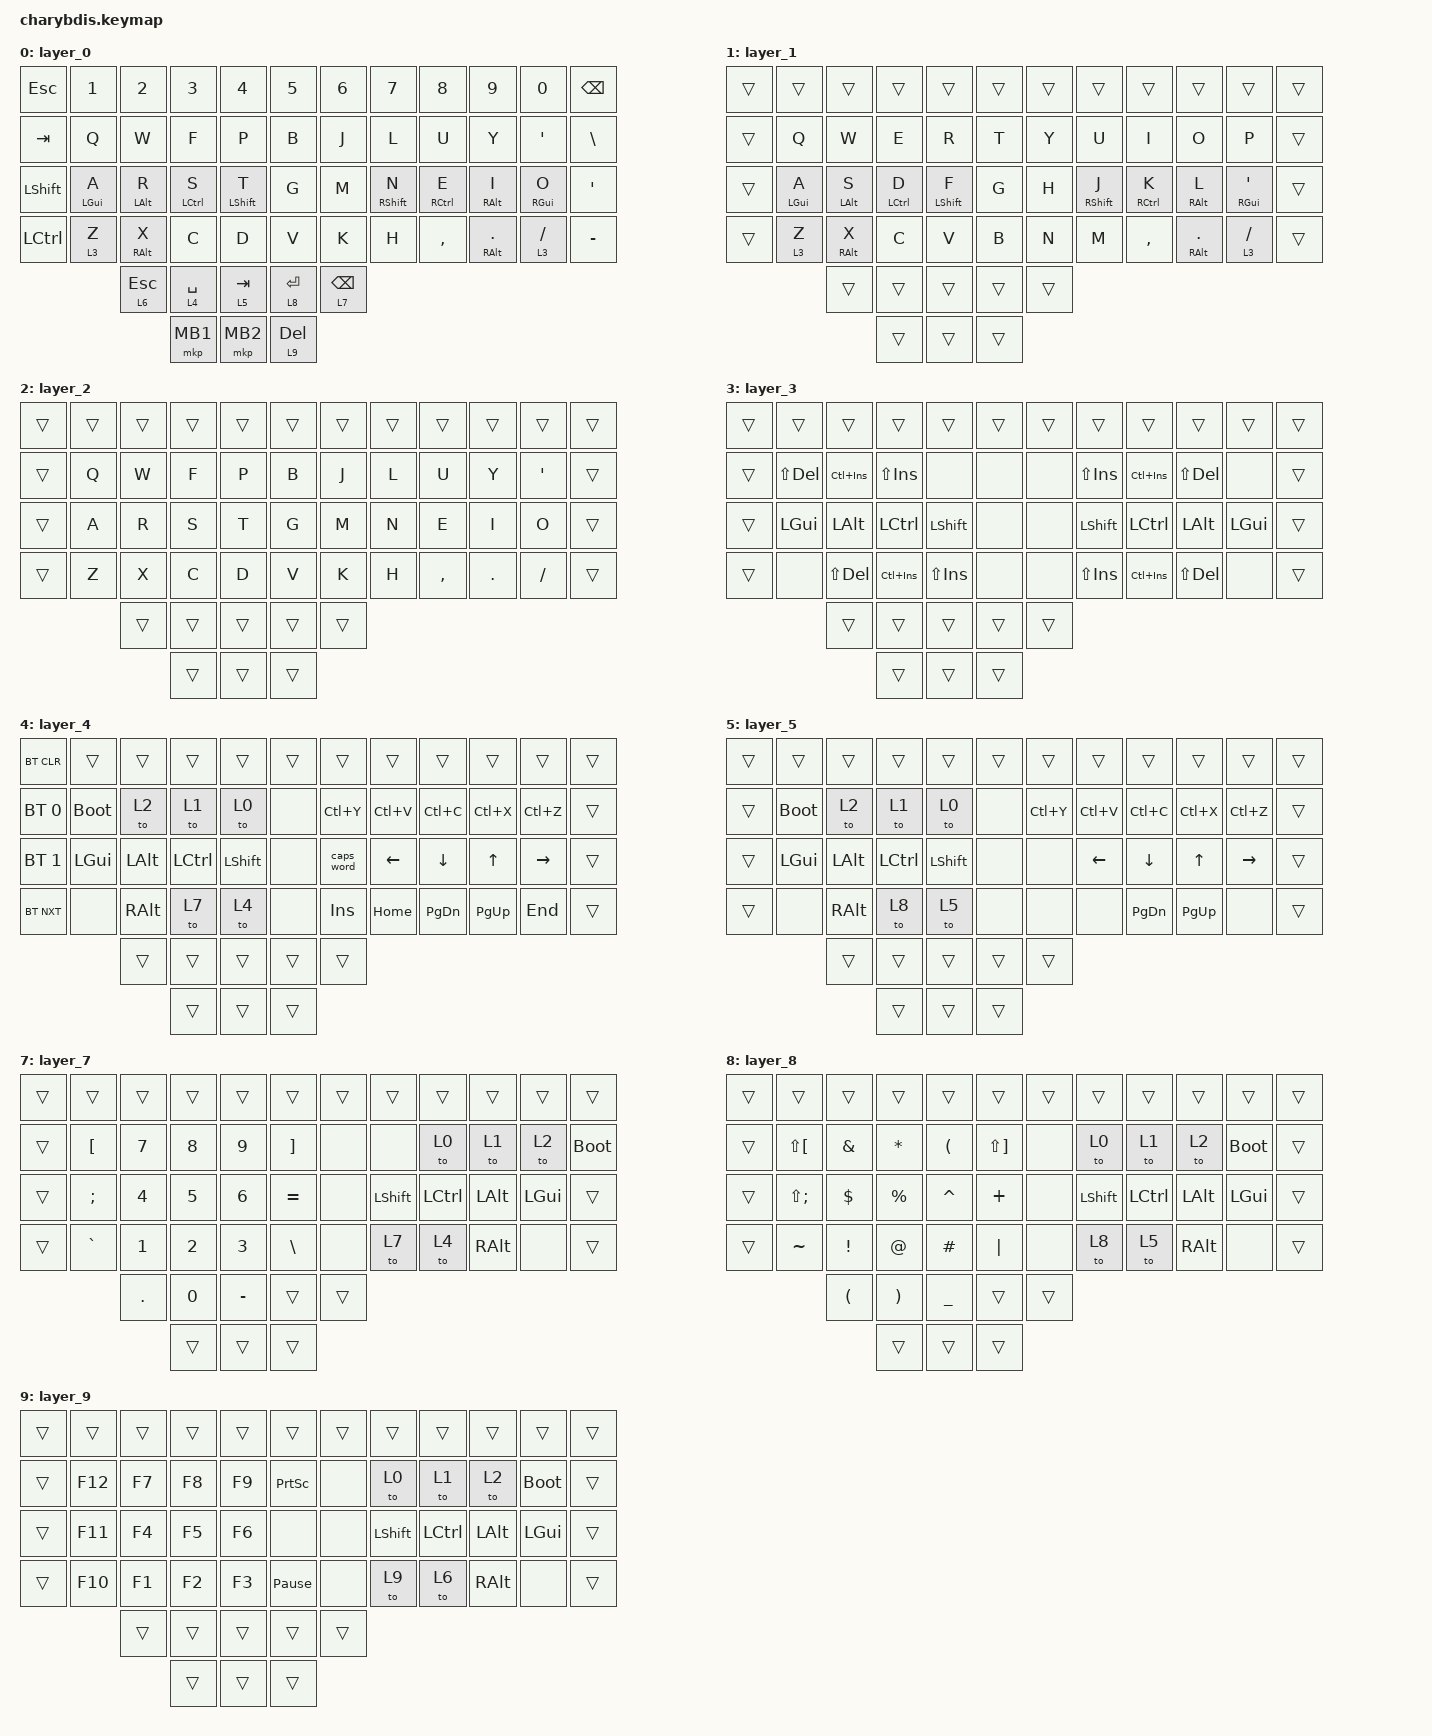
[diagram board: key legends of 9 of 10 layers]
#include <dt-bindings/zmk/mouse.h>
#include <behaviors.dtsi>
#include <dt-bindings/zmk/bt.h>
#include <dt-bindings/zmk/keys.h>
#include <dt-bindings/zmk/pointing.h>

&lt {
    tapping-term-ms = <500>;
    flavor = "balanced";
    quick-tap-ms = <150>;
};

/ {
    keymap {
        compatible = "zmk,keymap";

        layer_0 {
            bindings = <
&kp ESC         &kp N1  &kp N2  &kp N3        &kp N4     &kp N5      &kp N6     &kp N7     &kp N8     &kp N9            &kp N0    &kp BACKSPACE
&kp TAB         &kp Q   &kp W   &kp F         &kp P      &kp B       &kp J      &kp L      &kp U      &kp Y             &kp SQT   &kp BSLH
&kp LEFT_SHIFT  &mt LGUI A   &mt LALT R   &mt LCTRL S         &mt LSHFT T      &kp G       &kp M      &mt RSHFT N      &mt RCTRL E      &mt RALT I             &mt RGUI O     &kp SQT
    &kp LCTRL      &lt 3 Z       &mt RALT X   &kp C         &kp D      &kp V       &kp K      &kp H      &kp COMMA  &mt RALT DOT      &lt 3 SLASH  &kp MINUS
                    &lt 6 ESC      &lt 4 SPACE  &lt 5 TAB       &lt 8 ENTER   &lt 7 BACKSPACE
                                              &mkp MB1   &mkp MB2    &lt 9 DELETE
            >;

            trackball-bindings = <&tmv_coarse>;
        };

        layer_1 {
            bindings = <
&trans          &trans      &trans      &trans         &trans      &trans        &trans        &trans         &trans         &trans               &trans      &trans
    &trans          &kp Q       &kp W       &kp E          &kp R       &kp T         &kp Y         &kp U          &kp I          &kp O                &kp P       &trans
    &trans          &mt LGUI A  &mt LALT S  &mt LCTRL D    &mt LSHFT F &kp G         &kp H         &mt RSHFT J    &mt RCTRL K    &mt RALT L           &mt RGUI SQT &trans
    &trans          &lt 3 Z      &mt RALT X  &kp C          &kp V       &kp B         &kp N         &kp M          &kp COMMA      &mt RALT DOT         &lt 3 SLASH  &trans
                                &trans      &trans      &trans         &trans      &trans
                                              &trans      &trans         &trans
            >;

            trackball-bindings = <&tsl>;
        };

        layer_2 {
            bindings = <
&trans          &trans      &trans      &trans       &trans      &trans       &trans        &trans       &trans       &trans             &trans       &trans
    &trans          &kp Q       &kp W       &kp F        &kp P       &kp B        &kp J         &kp L        &kp U        &kp Y              &kp SQT      &trans
    &trans          &kp A       &kp R       &kp S        &kp T       &kp G        &kp M         &kp N        &kp E        &kp I              &kp O        &trans
    &trans          &kp Z       &kp X       &kp C        &kp D       &kp V        &kp K         &kp H        &kp COMMA    &kp DOT            &kp SLASH    &trans
                                &trans      &trans      &trans       &trans       &trans
                                              &trans      &trans       &trans
            >;

            trackball-bindings = <&tsl>;
        };

        layer_3 {
            bindings = <
&trans          &trans      &trans      &trans       &trans      &trans       &trans        &trans       &trans       &trans             &trans       &trans
    &trans          &kp LS(DEL) &kp LC(INS) &kp LS(INS)  &none       &none        &none         &kp LS(INS)  &kp LC(INS)  &kp LS(DEL)        &none        &trans
    &trans          &kp LGUI    &kp LALT    &kp LCTRL    &kp LSHFT   &none        &none         &kp LSHFT    &kp LCTRL    &kp LALT           &kp LGUI     &trans
    &trans          &none       &kp LS(DEL) &kp LC(INS)  &kp LS(INS) &none        &none         &kp LS(INS)  &kp LC(INS)  &kp LS(DEL)        &none        &trans
                                &trans      &trans      &trans       &trans       &trans
                                              &trans      &trans       &trans
            >;

            trackball-bindings = <&tsl>;
        };

        layer_4 {
            bindings = <
&bt BT_CLR      &trans      &trans      &trans       &trans      &trans       &trans          &trans        &trans            &trans             &trans       &trans
    &bt BT_SEL 0     &bootloader &to 2       &to 1        &to 0       &none        &kp LC(Y)      &kp LC(V)     &kp LC(C)        &kp LC(X)          &kp LC(Z)    &trans
    &bt BT_SEL 1     &kp LGUI    &kp LALT    &kp LCTRL    &kp LSHFT   &none        &caps_word     &kp LEFT      &kp DOWN         &kp UP             &kp RIGHT    &trans
    &bt BT_NXT       &none       &kp RALT    &to 7        &to 4       &none        &kp INS        &kp HOME      &kp PG_DN        &kp PG_UP          &kp END      &trans
                                &trans      &trans      &trans       &trans       &trans
                                              &trans      &trans       &trans
            >;

            trackball-bindings = <&tsl>;
        };

        layer_5 {
            bindings = <
&trans          &trans      &trans      &trans       &trans      &trans       &trans        &trans       &trans       &trans             &trans       &trans
&trans          &bootloader &to 2       &to 1        &to 0       &none        &kp LC(Y)      &kp LC(V)     &kp LC(C)        &kp LC(X)          &kp LC(Z)    &trans
&trans          &kp LGUI    &kp LALT    &kp LCTRL    &kp LSHFT   &none        &none         &kp LEFT      &kp DOWN         &kp UP             &kp RIGHT    &trans
&trans          &none       &kp RALT    &to 8        &to 5       &none        &none         &none         &kp PG_DN        &kp PG_UP          &none        &trans
                                &trans      &trans      &trans       &trans       &trans
                                              &trans      &trans       &trans
            >;

            trackball-bindings = <&tsl>;
        };

        layer_6 {
            bindings = <
&trans          &trans      &trans      &trans       &trans      &trans       &trans         &trans        &trans        &trans             &trans       &trans
&trans          &bootloader &to 2       &to 1        &to 0       &none        &none          &none         &none         &none              &none        &trans
&trans          &kp LGUI    &kp LALT    &kp LCTRL    &kp LSHFT   &none        &none          &kp C_PREV    &kp C_VOL_DN  &kp C_VOL_UP       &kp C_NEXT   &trans
&trans          &none       &kp RALT    &to 9        &to 6       &none        &none          &none         &none         &none              &none        &trans
&trans          &none       &none       &none        &none       &none        &none          &none         &none         &none              &none        &trans
                                &trans      &trans      &trans       &trans       &trans
                                              &trans      &trans       &trans
            >;

            trackball-bindings = <&tsl>;
        };

        layer_7 {
            bindings = <
&trans          &trans      &trans      &trans       &trans      &trans       &trans          &trans       &trans       &trans             &trans       &trans
&trans          &kp LEFT_BRACKET &kp N7      &kp N8       &kp N9       &kp RIGHT_BRACKET &none        &none            &to 0      &to 1       &to 2             &bootloader
&trans          &kp SEMI    &kp N4      &kp N5       &kp N6      &kp EQUAL    &none            &kp LSHFT   &kp LCTRL    &kp LALT           &kp LGUI     &trans
&trans          &kp GRAVE   &kp N1      &kp N2       &kp N3      &kp BSLH     &none            &to 7       &to 4        &kp RALT           &none        &trans
                                &kp PERIOD      &kp N0      &kp MINUS       &trans       &trans
                                              &trans      &trans       &trans
            >;

            trackball-bindings = <&tsl>;
        };

        layer_8 {
            bindings = <
&trans          &trans      &trans      &trans       &trans      &trans       &trans        &trans       &trans       &trans             &trans       &trans
&trans          &kp LS(LEFT_BRACKET)    &kp AMPS    &kp STAR     &kp LPAR    &kp LS(RIGHT_BRACKET)     &none     &to 0     &to 1     &to 2          &bootloader     &trans
&trans          &kp LS(SEMI)    &kp DLLR    &kp PRCNT    &kp CARET   &kp PLUS        &none      &kp LSHFT     &kp LCTRL    &kp LALT          &kp LGUI     &trans
&trans          &kp TILDE       &kp EXCL    &kp AT       &kp HASH    &kp PIPE        &none      &to 8         &to 5       &kp RALT          &none        &trans
                                &kp LEFT_PARENTHESIS      &kp RIGHT_PARENTHESIS      &kp UNDERSCORE       &trans       &trans
                                              &trans      &trans       &trans
            >;

            trackball-bindings = <&tsl>;
        };

        layer_9 {
            bindings = <
&trans          &trans      &trans      &trans       &trans      &trans       &trans        &trans       &trans       &trans             &trans       &trans
&trans          &kp F12     &kp F7      &kp F8       &kp F9      &kp PSCRN    &none         &to 0        &to 1        &to 2              &bootloader  &trans
&trans          &kp F11     &kp F4      &kp F5       &kp F6      &none        &none         &kp LSHFT    &kp LCTRL    &kp LALT           &kp LGUI     &trans
&trans          &kp F10     &kp F1      &kp F2       &kp F3      &kp PAUSE_BREAK &none      &to 9        &to 6        &kp RALT           &none        &trans
                                &trans      &trans      &trans       &trans       &trans
                                              &trans      &trans       &trans
            >;

            trackball-bindings = <&tsl>;
        };

        /* layer_6 {
            bindings = <
&none  &none   &none    &none   &none         &none         &kp N1         &none         &none     &none  &none   &to 0
&none  &none   &none    &none   &none         &none         &none         &none          &rgb_ug RGB_BRD &rgb_ug RGB_BRI  &rgb_ug RGB_EFF   &rgb_ug RGB_TOG
&none  &none   &none    &none   &none         &none         &none         &mkp LCLK     &mkp RCLK  &none  &none   &none
&none  &none   &none    &none   &bt BT_NXT  &bt BT_CLR    &none         &none         &none     &none  &none   &none
                                   &none         &none         &none         &none         &none
                                                 &none         &none         &none
            >;
          trackball-bindings = <&tsl>;
            
        };

       Mouse {
            bindings = <
&none        &none         &none         &none         &none      &none         &none       &none      &none         &none         &none         &none
&none        &bt BT_SEL 0  &bt BT_SEL 1  &bt BT_SEL 3  &none      &bt BT_CLR    &bt BT_CLR  &none      &bt BT_SEL 2  &bt BT_SEL 1  &bt BT_SEL 0  &none
&none        &trans        &trans        &mkp MCLK     &trans     &none         &none       &trans     &mkp MCLK     &trans        &trans        &none
&bootloader  &trans        &mkp RCLK     &mo 4         &mkp LCLK  &mo 5         &mo 5       &mkp LCLK  &mo 4         &mkp RCLK     &trans        &bootloader
                                         &mo 5         &mkp LCLK  &mkp RCLK     &mkp RCLK   &mkp LCLK
                                                       &none      &trans        &trans
            >;

            
        };

        layer_4 {
            bindings = <
&trans  &trans  &trans     &trans     &trans     &trans       &trans     &trans     &trans     &trans     &trans  &trans
&trans  &trans  &trans     &trans     &trans     &trans       &trans     &trans     &trans     &trans     &trans  &trans
&trans  &trans  &trans     &mkp MCLK  &trans     &trans       &trans     &trans     &mkp MCLK  &trans     &trans  &trans
&trans  &trans  &mkp RCLK  &trans     &mkp LCLK  &trans       &trans     &mkp LCLK  &trans     &mkp RCLK  &trans  &trans
                           &trans     &mkp LCLK  &mkp RCLK    &mkp RCLK  &mkp LCLK
                                      &trans     &trans       &trans
            >;
                
                
                trackball-bindings = <&tsl>;
        };

        layer_5 {
            bindings = <
&trans  &trans  &trans     &trans     &trans     &trans       &trans     &trans     &trans     &trans     &trans  &trans
&trans  &trans  &trans     &trans     &trans     &trans       &trans     &trans     &trans     &trans     &trans  &trans
&trans  &trans  &trans     &mkp MCLK  &trans     &trans       &trans     &trans     &mkp MCLK  &trans     &trans  &trans
&trans  &trans  &mkp RCLK  &trans     &mkp LCLK  &trans       &trans     &mkp LCLK  &trans     &mkp RCLK  &trans  &trans
                           &trans     &mkp LCLK  &mkp RCLK    &mkp RCLK  &mkp LCLK
                                      &trans     &trans       &trans
            >;
                trackball-bindings = <&tmv_fine>;
                
        };*/
    };
};
